AUTOSAR XML (schema 00046)
package /ComponentTypes
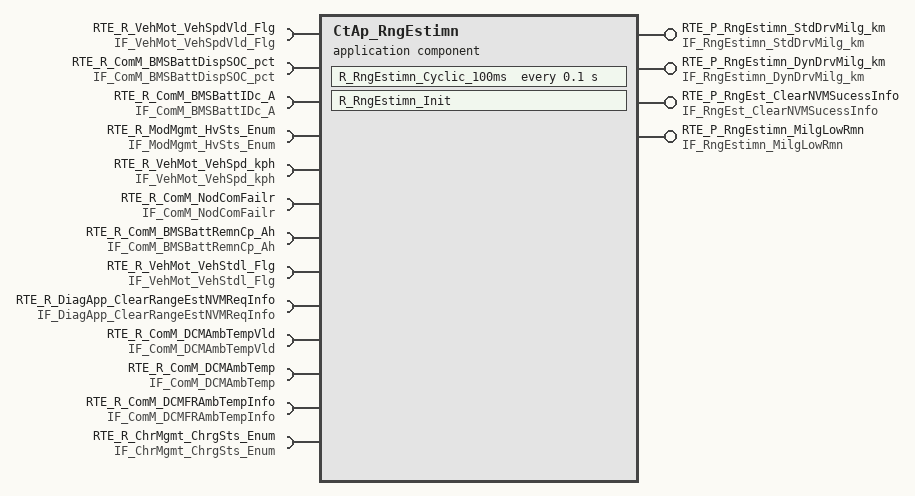
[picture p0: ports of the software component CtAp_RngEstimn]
  application sw component type CtAp_RngEstimn
    provide port RTE_P_RngEstimn_StdDrvMilg_km: nonqueued-sender-com-spec{data-element=tec_RngEstimn_StdDrvMilg_km, init-value=0}, provided-interface=IF_RngEstimn_StdDrvMilg_km
    provide port RTE_P_RngEstimn_DynDrvMilg_km: nonqueued-sender-com-spec{data-element=tec_RngEstimn_DynDrvMilg_km, init-value=0}, provided-interface=IF_RngEstimn_DynDrvMilg_km
    6 x require port:
      RTE_R_VehMot_VehSpdVld_Flg: nonqueued-receiver-com-spec{data-element=tec_VehMot_VehSpdVld_Flg, filter=data-filter-type=ALWAYS, init-value=0}, required-interface=IF_VehMot_VehSpdVld_Flg
      RTE_R_ComM_BMSBattDispSOC_pct: nonqueued-receiver-com-spec{data-element=tec_ComM_BMSBattDispSOC_pct, filter=data-filter-type=ALWAYS, init-value=0}, required-interface=IF_ComM_BMSBattDispSOC_pct
      RTE_R_ComM_BMSBattIDc_A: nonqueued-receiver-com-spec{data-element=tec_ComM_BMSBattIDc_A, filter=data-filter-type=ALWAYS, init-value=0}, required-interface=IF_ComM_BMSBattIDc_A
      RTE_R_ModMgmt_HvSts_Enum: nonqueued-receiver-com-spec{data-element=tec_ModMgmt_HvSts_Enum, filter=data-filter-type=ALWAYS, init-value=0}, required-interface=IF_ModMgmt_HvSts_Enum
      RTE_R_VehMot_VehSpd_kph: nonqueued-receiver-com-spec{data-element=tec_VehMot_VehSpd_kph, filter=data-filter-type=ALWAYS, init-value=0}, required-interface=IF_VehMot_VehSpd_kph
      RTE_R_ComM_NodComFailr: required-interface=IF_ComM_NodComFailr
        required-com-specs:
          data-element=tec_ComM_SGWNodComFailr_Flg, filter=data-filter-type=ALWAYS, init-value=0
          data-element=tec_ComM_CGWNodComFailr_Flg, filter=data-filter-type=ALWAYS, init-value=0
          data-element=tec_ComM_TCUNodComFailr_Flg, filter=data-filter-type=ALWAYS, init-value=0
          data-element=tec_ComM_BCMNodComFailr_Flg, filter=data-filter-type=ALWAYS, init-value=0
          data-element=tec_ComM_PRNDNodComFailr_Flg, filter=data-filter-type=ALWAYS, init-value=0
          data-element=tec_ComM_IVINodComFailr_Flg, filter=data-filter-type=ALWAYS, init-value=0
          data-element=tec_ComM_DCDCNodComFailr_Flg, filter=data-filter-type=ALWAYS, init-value=0
          data-element=tec_ComM_OBCNodComFailr_Flg, filter=data-filter-type=ALWAYS, init-value=0
          data-element=tec_ComM_CHIBSNodComFailr_Flg, filter=data-filter-type=ALWAYS, init-value=0
          data-element=tec_ComM_MCUNodComFailr_Flg, filter=data-filter-type=ALWAYS, init-value=0
          data-element=tec_ComM_EVCOMNodComFailr_Flg, filter=data-filter-type=ALWAYS, init-value=0
          data-element=tec_ComM_EPTIBSNodComFailr_Flg, filter=data-filter-type=ALWAYS, init-value=0
          data-element=tec_ComM_DCMNodComFailr_Flg, filter=data-filter-type=ALWAYS, init-value=0
          data-element=tec_ComM_BMSNodComFailr_Flg, filter=data-filter-type=ALWAYS, init-value=0
          data-element=tec_ComM_ACUNodComFailr_Flg, filter=data-filter-type=ALWAYS, init-value=0
          data-element=tec_ComM_APTCNodComFailr_Flg, filter=data-filter-type=ALWAYS, init-value=0
          data-element=tec_ComM_ADCUNodComFailr_Flg, filter=data-filter-type=ALWAYS, init-value=0
          data-element=tec_ComM_DCMRRNodComFailr_Flg, filter=data-filter-type=ALWAYS, init-value=0
          data-element=tec_ComM_DCMRLNodComFailr_Flg, filter=data-filter-type=ALWAYS, init-value=0
          data-element=tec_ComM_DCMFRNodComFailr_Flg, filter=data-filter-type=ALWAYS, init-value=0
          data-element=tec_ComM_DCMFLNodComFailr_Flg, filter=data-filter-type=ALWAYS, init-value=0
          data-element=tec_ComM_SGWCHNodComFailr_Flg, init-value=0
    provide/require port RTE_RP_RngEstimnInfo: nv-provide-com-spec{ram-block-init-value=fields=[RngEstimn_BMSBattIDcIntgl_As:0, RngEstimn_AccuMilg_m:0], rom-block-init-value=fields=[RngEstimn_BMSBattIDcIntgl_As:0, RngEstimn_AccuMilg_m:0], variable=tec_RngEstimnInfo}, nv-require-com-spec{init-value=fields=[RngEstimn_BMSBattIDcIntgl_As:0, RngEstimn_AccuMilg_m:0], variable=tec_RngEstimnInfo}, provided-required-interface=IF_RngEstimnInfo
    require port RTE_R_ComM_BMSBattRemnCp_Ah: nonqueued-receiver-com-spec{data-element=tec_ComM_BMSBattRemnCp_Ah, filter=data-filter-type=ALWAYS, init-value=0}, required-interface=IF_ComM_BMSBattRemnCp_Ah
    require port RTE_R_VehMot_VehStdl_Flg: nonqueued-receiver-com-spec{data-element=tec_VehMot_VehStdl_Flg, filter=data-filter-type=ALWAYS, init-value=0}, required-interface=IF_VehMot_VehStdl_Flg
    provide port RTE_P_RngEst_ClearNVMSucessInfo: nonqueued-sender-com-spec{data-element=tec_RngEst_ClearNVMSucessInfo, init-value=0}, provided-interface=IF_RngEst_ClearNVMSucessInfo
    require port RTE_R_DiagApp_ClearRangeEstNVMReqInfo: nonqueued-receiver-com-spec{data-element=tec_DiagApp_ClearRangeEstNVMReqInfo, filter=data-filter-type=ALWAYS, init-value=0}, required-interface=IF_DiagApp_ClearRangeEstNVMReqInfo
    provide port RTE_P_RngEstimn_MilgLowRmn: nonqueued-sender-com-spec{data-element=tec_RngEstimn_MilgLowRmn, init-value=0}, provided-interface=IF_RngEstimn_MilgLowRmn
    4 x require port:
      RTE_R_ComM_DCMAmbTempVld: nonqueued-receiver-com-spec{data-element=tec_ComM_DCMAmbTempVld, filter=data-filter-type=ALWAYS, init-value=0}, required-interface=IF_ComM_DCMAmbTempVld
      RTE_R_ComM_DCMAmbTemp: nonqueued-receiver-com-spec{data-element=tec_ComM_DCMAmbTemp, filter=data-filter-type=ALWAYS, init-value=0}, required-interface=IF_ComM_DCMAmbTemp
      RTE_R_ComM_DCMFRAmbTempInfo: nonqueued-receiver-com-spec{data-element=tec_ComM_DCMFRAmbTempInfo, filter=data-filter-type=ALWAYS}, required-interface=IF_ComM_DCMFRAmbTempInfo
      RTE_R_ChrMgmt_ChrgSts_Enum: nonqueued-receiver-com-spec{data-element=tec_ChrMgmt_ChrgSts_Enum, filter=data-filter-type=ALWAYS, init-value=0}, required-interface=IF_ChrMgmt_ChrgSts_Enum
    provide/require port RTE_RP_RngEstimnFormual2: nv-provide-com-spec{ram-block-init-value=25 x 3197, rom-block-init-value=25 x 3197, variable=tec_RngEstimnFormual2}, nv-require-com-spec{init-value=25 x 3197, variable=tec_RngEstimnFormual2}, provided-required-interface=IF_RngEstimnFormual2
    behavior CtAp_RngEstimn_InternalBehavior
      init event CtAp_RngEstimn_InitEvent: start-on-event=R_RngEstimn_Init
      timing event TMT_R_RngEstimn_Cyclic_100ms: start-on-event=R_RngEstimn_Cyclic_100ms, period=0.1
      runnable R_RngEstimn_Cyclic_100ms
        data-receive-point-by-arguments:
          15 x access:
            REC_RTE_R_ComM_BMSBattDispSOC_pct_tec_ComM_BMSBattDispSOC_pct: accessed-variable=RTE_R_ComM_BMSBattDispSOC_pct.tec_ComM_BMSBattDispSOC_pct
            REC_RTE_R_ComM_BMSBattIDc_A_tec_ComM_BMSBattIDc_A: accessed-variable=RTE_R_ComM_BMSBattIDc_A.tec_ComM_BMSBattIDc_A
            REC_RTE_R_ComM_NodComFailr_tec_ComM_BMSNodComFailr_Flg: accessed-variable=RTE_R_ComM_NodComFailr.tec_ComM_BMSNodComFailr_Flg
            REC_RTE_R_ModMgmt_HvSts_Enum_tec_ModMgmt_HvSts_Enum: accessed-variable=RTE_R_ModMgmt_HvSts_Enum.tec_ModMgmt_HvSts_Enum
            REC_RTE_R_VehMot_VehSpdVld_Flg_tec_VehMot_VehSpdVld_Flg: accessed-variable=RTE_R_VehMot_VehSpdVld_Flg.tec_VehMot_VehSpdVld_Flg
            REC_RTE_R_VehMot_VehSpd_kph_tec_VehMot_VehSpd_kph: accessed-variable=RTE_R_VehMot_VehSpd_kph.tec_VehMot_VehSpd_kph
            REC_RTE_RP_RngEstimnInfo_tec_RngEstimnInfo: accessed-variable=RTE_RP_RngEstimnInfo.tec_RngEstimnInfo
            REC_RTE_R_ComM_BMSBattRemnCp_Ah_tec_ComM_BMSBattRemnCp_Ah: accessed-variable=RTE_R_ComM_BMSBattRemnCp_Ah.tec_ComM_BMSBattRemnCp_Ah
            REC_RTE_R_VehMot_VehStdl_Flg_tec_VehMot_VehStdl_Flg: accessed-variable=RTE_R_VehMot_VehStdl_Flg.tec_VehMot_VehStdl_Flg
            REC_RTE_R_DiagApp_ClearRangeEstNVMReqInfo_tec_DiagApp_ClearRangeEstNVMReqInfo: accessed-variable=RTE_R_DiagApp_ClearRangeEstNVMReqInfo.tec_DiagApp_ClearRangeEstNVMReqInfo
            REC_RTE_R_ComM_DCMAmbTemp_tec_ComM_DCMAmbTemp: accessed-variable=RTE_R_ComM_DCMAmbTemp.tec_ComM_DCMAmbTemp
            REC_RTE_R_ComM_DCMAmbTempVld_tec_ComM_DCMAmbTempVld: accessed-variable=RTE_R_ComM_DCMAmbTempVld.tec_ComM_DCMAmbTempVld
            REC_RTE_R_ChrMgmt_ChrgSts_Enum_tec_ChrMgmt_ChrgSts_Enum: accessed-variable=RTE_R_ChrMgmt_ChrgSts_Enum.tec_ChrMgmt_ChrgSts_Enum
            REC_RTE_R_ComM_DCMFRAmbTempInfo_tec_ComM_DCMFRAmbTempInfo: accessed-variable=RTE_R_ComM_DCMFRAmbTempInfo.tec_ComM_DCMFRAmbTempInfo
            REC_RTE_RP_RngEstimnFormual2_tec_RngEstimnFormual2: accessed-variable=RTE_RP_RngEstimnFormual2.tec_RngEstimnFormual2
        data-send-points:
          6 x access:
            SEND_RTE_P_RngEstimn_DynDrvMilg_km_tec_RngEstimn_DynDrvMilg_km: accessed-variable=RTE_P_RngEstimn_DynDrvMilg_km.tec_RngEstimn_DynDrvMilg_km
            SEND_RTE_P_RngEstimn_StdDrvMilg_km_tec_RngEstimn_StdDrvMilg_km: accessed-variable=RTE_P_RngEstimn_StdDrvMilg_km.tec_RngEstimn_StdDrvMilg_km
            SEND_RTE_RP_RngEstimnInfo_tec_RngEstimnInfo: accessed-variable=RTE_RP_RngEstimnInfo.tec_RngEstimnInfo
            SEND_RTE_P_RngEst_ClearNVMSucessInfo_tec_RngEst_ClearNVMSucessInfo: accessed-variable=RTE_P_RngEst_ClearNVMSucessInfo.tec_RngEst_ClearNVMSucessInfo
            SEND_RTE_P_RngEstimn_MilgLowRmn_tec_RngEstimn_MilgLowRmn: accessed-variable=RTE_P_RngEstimn_MilgLowRmn.tec_RngEstimn_MilgLowRmn
            SEND_RTE_RP_RngEstimnFormual2_tec_RngEstimnFormual2: accessed-variable=RTE_RP_RngEstimnFormual2.tec_RngEstimnFormual2
      runnable R_RngEstimn_Init
  swc implementation CtAp_RngEstimn_Implementation: behavior=CtAp_RngEstimn_InternalBehavior
